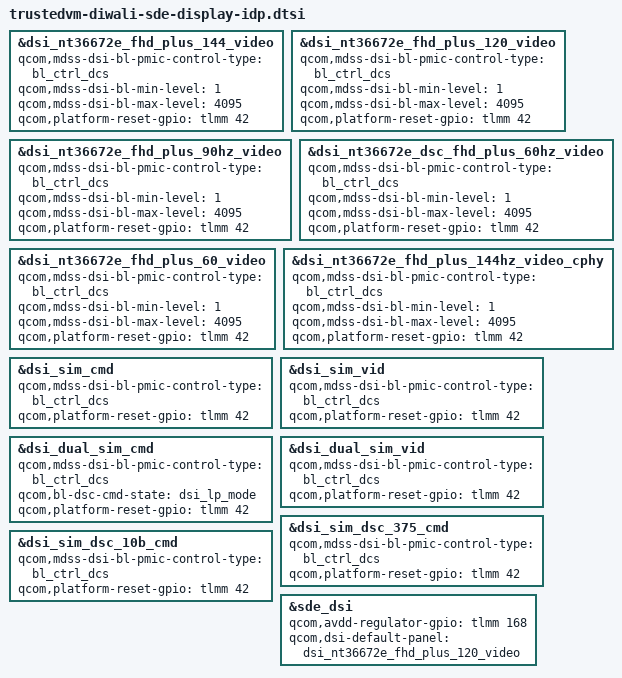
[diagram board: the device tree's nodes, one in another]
#include "trustedvm-diwali-sde-display.dtsi"

&dsi_nt36672e_fhd_plus_144_video {
	qcom,mdss-dsi-bl-pmic-control-type = "bl_ctrl_dcs";
	qcom,mdss-dsi-bl-min-level = <1>;
	qcom,mdss-dsi-bl-max-level = <4095>;
	qcom,platform-reset-gpio = <&tlmm 42 0>;
};

&dsi_nt36672e_fhd_plus_120_video {
	qcom,mdss-dsi-bl-pmic-control-type = "bl_ctrl_dcs";
	qcom,mdss-dsi-bl-min-level = <1>;
	qcom,mdss-dsi-bl-max-level = <4095>;
	qcom,platform-reset-gpio = <&tlmm 42 0>;
};

&dsi_nt36672e_fhd_plus_90hz_video {
	qcom,mdss-dsi-bl-pmic-control-type = "bl_ctrl_dcs";
	qcom,mdss-dsi-bl-min-level = <1>;
	qcom,mdss-dsi-bl-max-level = <4095>;
	qcom,platform-reset-gpio = <&tlmm 42 0>;
};

&dsi_nt36672e_dsc_fhd_plus_60hz_video {
	qcom,mdss-dsi-bl-pmic-control-type = "bl_ctrl_dcs";
	qcom,mdss-dsi-bl-min-level = <1>;
	qcom,mdss-dsi-bl-max-level = <4095>;
	qcom,platform-reset-gpio = <&tlmm 42 0>;
};

&dsi_nt36672e_fhd_plus_60_video {
	qcom,mdss-dsi-bl-pmic-control-type = "bl_ctrl_dcs";
	qcom,mdss-dsi-bl-min-level = <1>;
	qcom,mdss-dsi-bl-max-level = <4095>;
	qcom,platform-reset-gpio = <&tlmm 42 0>;
};

&dsi_nt36672e_fhd_plus_144hz_video_cphy {
	qcom,mdss-dsi-bl-pmic-control-type = "bl_ctrl_dcs";
	qcom,mdss-dsi-bl-min-level = <1>;
	qcom,mdss-dsi-bl-max-level = <4095>;
	qcom,platform-reset-gpio = <&tlmm 42 0>;
};

&dsi_sim_cmd {
	qcom,mdss-dsi-bl-pmic-control-type = "bl_ctrl_dcs";
	qcom,platform-reset-gpio = <&tlmm 42 0>;
};

&dsi_sim_vid {
	qcom,mdss-dsi-bl-pmic-control-type = "bl_ctrl_dcs";
	qcom,platform-reset-gpio = <&tlmm 42 0>;
};

&dsi_dual_sim_cmd {
	qcom,mdss-dsi-bl-pmic-control-type = "bl_ctrl_dcs";
	qcom,bl-dsc-cmd-state = "dsi_lp_mode";
	qcom,platform-reset-gpio = <&tlmm 42 0>;
};

&dsi_dual_sim_vid {
	qcom,mdss-dsi-bl-pmic-control-type = "bl_ctrl_dcs";
	qcom,platform-reset-gpio = <&tlmm 42 0>;
};

&dsi_sim_dsc_375_cmd {
	qcom,mdss-dsi-bl-pmic-control-type = "bl_ctrl_dcs";
	qcom,platform-reset-gpio = <&tlmm 42 0>;
};

&dsi_sim_dsc_10b_cmd {
	qcom,mdss-dsi-bl-pmic-control-type = "bl_ctrl_dcs";
	qcom,platform-reset-gpio = <&tlmm 42 0>;
};

&sde_dsi {
	qcom,avdd-regulator-gpio = <&tlmm 168 0>;
	qcom,dsi-default-panel = <&dsi_nt36672e_fhd_plus_120_video>;
};
